VERSION ""

NS_ :

BS_:

BU_: XXX

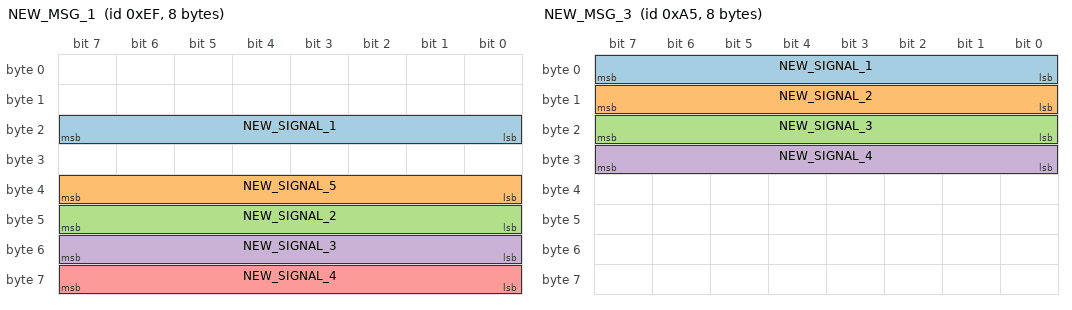
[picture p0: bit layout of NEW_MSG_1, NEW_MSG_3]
BO_ 239 NEW_MSG_1: 8 XXX
 SG_ NEW_SIGNAL_1 : 23|8@0+ (1,0) [0|255] "" XXX
 SG_ NEW_SIGNAL_5 : 39|8@0+ (1,0) [0|255] "" XXX
 SG_ NEW_SIGNAL_2 : 40|8@1+ (1,0) [0|255] "" XXX
 SG_ NEW_SIGNAL_3 : 48|8@1+ (1,0) [0|255] "" XXX
 SG_ NEW_SIGNAL_4 : 56|8@1+ (1,0) [0|255] "" XXX

BO_ 217 NEW_MSG_2: 8 XXX
 SG_ Accelerator_pressed : 63|8@0+ (1,0) [0|255] "" XXX
 SG_ NEW_SIGNAL_1 : 16|16@1+ (1,0) [0|65535] "" XXX

BO_ 165 NEW_MSG_3: 8 XXX
 SG_ NEW_SIGNAL_1 : 7|8@0+ (1,0) [0|255] "" XXX
 SG_ NEW_SIGNAL_2 : 15|8@0+ (1,0) [0|255] "" XXX
 SG_ NEW_SIGNAL_3 : 23|8@0+ (1,0) [0|255] "" XXX
 SG_ NEW_SIGNAL_4 : 31|8@0+ (1,0) [0|255] "" XXX

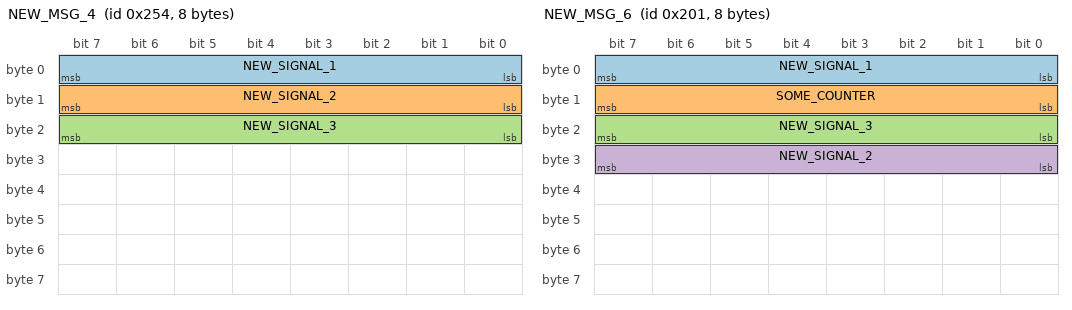
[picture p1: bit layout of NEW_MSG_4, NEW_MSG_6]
BO_ 596 NEW_MSG_4: 8 XXX
 SG_ NEW_SIGNAL_1 : 0|8@1+ (1,0) [0|255] "" XXX
 SG_ NEW_SIGNAL_2 : 8|8@1+ (1,0) [0|255] "" XXX
 SG_ NEW_SIGNAL_3 : 16|8@1+ (1,0) [0|255] "" XXX

BO_ 407 NEW_MSG_5: 8 XXX
 SG_ NEW_SIGNAL_1 : 0|8@1+ (1,0) [0|255] "" XXX
 SG_ NEW_SIGNAL_2 : 8|8@1+ (1,0) [0|255] "" XXX

BO_ 513 NEW_MSG_6: 8 XXX
 SG_ NEW_SIGNAL_1 : 0|8@1+ (1,0) [0|255] "" XXX
 SG_ SOME_COUNTER : 15|8@0+ (1,0) [0|255] "" XXX
 SG_ NEW_SIGNAL_3 : 16|8@1+ (1,0) [0|255] "" XXX
 SG_ NEW_SIGNAL_2 : 24|8@1+ (1,0) [0|255] "" XXX

BO_ 518 NEW_MSG_7: 8 XXX
 SG_ NEW_SIGNAL_1 : 7|8@0+ (1,0) [0|255] "" XXX
 SG_ NEW_SIGNAL_2 : 15|8@0+ (1,0) [0|255] "" XXX

BO_ 709 NEW_MSG_8: 8 XXX
 SG_ NEW_SIGNAL_1 : 7|8@0+ (1,0) [0|255] "" XXX
 SG_ NEW_SIGNAL_2 : 16|16@1+ (1,0) [0|255] "" XXX

BO_ 256 NEW_MSG_9: 8 XXX
 SG_ ePower : 39|8@0+ (1,0) [0|255] "" XXX

BO_ 417 NEW_MSG_10: 8 XXX
 SG_ Speed : 16|16@1+ (0.1,0) [0|65535] "MPH" XXX

BO_ 770 NEW_MSG_11: 8 XXX
 SG_ STEERING_ANGLE : 16|16@1+ (0.002747,-90) [0|65535] "DEG" XXX
